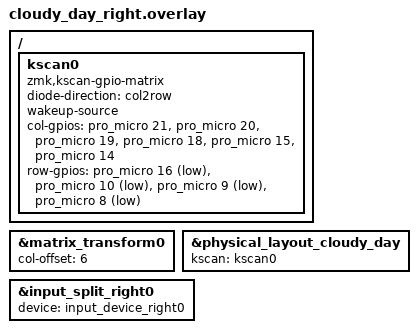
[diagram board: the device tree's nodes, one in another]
#include "cloudy_day.dtsi"

/ {
    kscan0: kscan0 {
        compatible = "zmk,kscan-gpio-matrix";
        diode-direction = "col2row";
        wakeup-source;

        col-gpios
            = <&pro_micro 21 GPIO_ACTIVE_HIGH>
            , <&pro_micro 20 GPIO_ACTIVE_HIGH>
            , <&pro_micro 19 GPIO_ACTIVE_HIGH>
            , <&pro_micro 18 GPIO_ACTIVE_HIGH>
            , <&pro_micro 15 GPIO_ACTIVE_HIGH>
            , <&pro_micro 14 GPIO_ACTIVE_HIGH>
            ;

        row-gpios
            = <&pro_micro 16 (GPIO_ACTIVE_LOW | GPIO_PULL_UP)>
            , <&pro_micro 10 (GPIO_ACTIVE_LOW | GPIO_PULL_UP)>
            , <&pro_micro  9 (GPIO_ACTIVE_LOW | GPIO_PULL_UP)>
            , <&pro_micro  8 (GPIO_ACTIVE_LOW | GPIO_PULL_UP)>
            ;
    };
};

&matrix_transform0 {
    col-offset = <6>;
};

&physical_layout_cloudy_day {
    kscan = <&kscan0>;
};
// == Input devices ==
// Enabling input-split for its own input devices
// Adding input devices and assigning them to input-split
&input_split_right0 {
    status = "okay";
    device = <&input_device_right0>;
};

